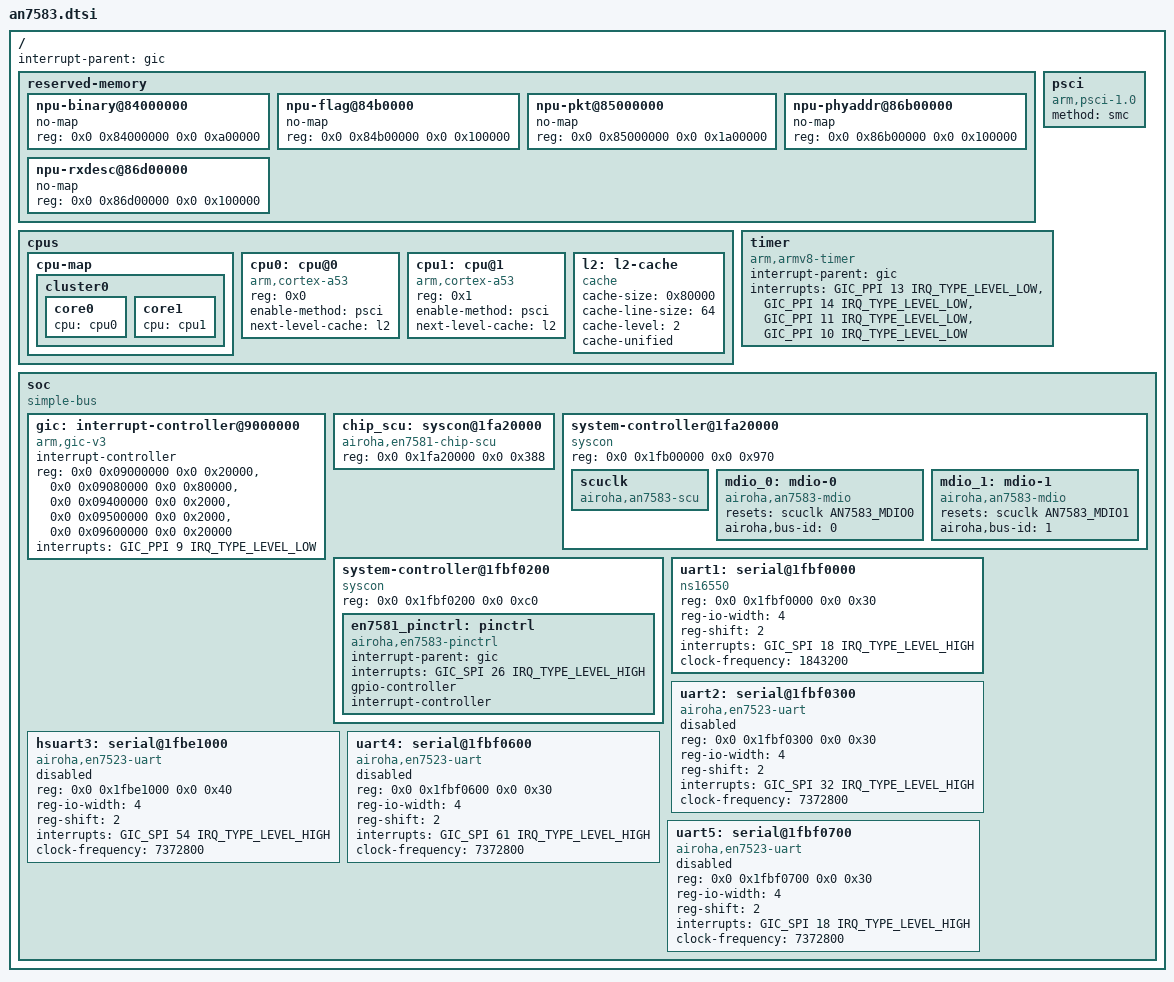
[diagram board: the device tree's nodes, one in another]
// SPDX-License-Identifier: (GPL-2.0-only OR BSD-2-Clause)

#include <dt-bindings/interrupt-controller/irq.h>
#include <dt-bindings/interrupt-controller/arm-gic.h>
#include <dt-bindings/clock/en7523-clk.h>
#include <dt-bindings/reset/airoha,an7583-reset.h>
#include <dt-bindings/leds/common.h>
#include <dt-bindings/thermal/thermal.h>

/ {
	interrupt-parent = <&gic>;
	#address-cells = <2>;
	#size-cells = <2>;

	reserved-memory {
		#address-cells = <2>;
		#size-cells = <2>;
		ranges;

		npu-binary@84000000 {
			no-map;
			reg = <0x0 0x84000000 0x0 0xa00000>;
		};

		npu-flag@84b0000 {
			no-map;
			reg = <0x0 0x84b00000 0x0 0x100000>;
		};

		npu-pkt@85000000 {
			no-map;
			reg = <0x0 0x85000000 0x0 0x1a00000>;
		};

		npu-phyaddr@86b00000 {
			no-map;
			reg = <0x0 0x86b00000 0x0 0x100000>;
		};

		npu-rxdesc@86d00000 {
			no-map;
			reg = <0x0 0x86d00000 0x0 0x100000>;
		};
	};

	psci {
		compatible = "arm,psci-1.0";
		method = "smc";
	};

	cpus {
		#address-cells = <1>;
		#size-cells = <0>;

		cpu-map {
			cluster0 {
				core0 {
					cpu = <&cpu0>;
				};

				core1 {
					cpu = <&cpu1>;
				};
			};
		};

		cpu0: cpu@0 {
			device_type = "cpu";
			compatible = "arm,cortex-a53";
			reg = <0x0>;
			enable-method = "psci";
			next-level-cache = <&l2>;
			#cooling-cells = <2>;
		};

		cpu1: cpu@1 {
			device_type = "cpu";
			compatible = "arm,cortex-a53";
			reg = <0x1>;
			enable-method = "psci";
			next-level-cache = <&l2>;
			#cooling-cells = <2>;
		};

		l2: l2-cache {
			compatible = "cache";
			cache-size = <0x80000>;
			cache-line-size = <64>;
			cache-level = <2>;
			cache-unified;
		};
	};

	timer {
		compatible = "arm,armv8-timer";
		interrupt-parent = <&gic>;
		interrupts = <GIC_PPI 13 IRQ_TYPE_LEVEL_LOW>,
			     <GIC_PPI 14 IRQ_TYPE_LEVEL_LOW>,
			     <GIC_PPI 11 IRQ_TYPE_LEVEL_LOW>,
			     <GIC_PPI 10 IRQ_TYPE_LEVEL_LOW>;
	};

	soc {
		compatible = "simple-bus";
		#address-cells = <2>;
		#size-cells = <2>;
		ranges;

		gic: interrupt-controller@9000000 {
			compatible = "arm,gic-v3";
			interrupt-controller;
			#interrupt-cells = <3>;
			#address-cells = <1>;
			#size-cells = <1>;
			reg = <0x0 0x09000000 0x0 0x20000>,
			      <0x0 0x09080000 0x0 0x80000>,
			      <0x0 0x09400000 0x0 0x2000>,
			      <0x0 0x09500000 0x0 0x2000>,
			      <0x0 0x09600000 0x0 0x20000>;
			interrupts = <GIC_PPI 9 IRQ_TYPE_LEVEL_LOW>;
		};

		chip_scu: syscon@1fa20000 {
			compatible = "airoha,en7581-chip-scu", "syscon";
			reg = <0x0 0x1fa20000 0x0 0x388>;
		};

		system-controller@1fa20000 {
			compatible = "syscon", "simple-mfd";
			reg = <0x0 0x1fb00000 0x0 0x970>;

			scuclk: scuclk {
				compatible = "airoha,an7583-scu";
				#clock-cells = <1>;
				#reset-cells = <1>;
			};

			mdio_0: mdio-0 {
				compatible = "airoha,an7583-mdio";
				resets = <&scuclk AN7583_MDIO0>;

				airoha,bus-id = <0>;
			};

			mdio_1: mdio-1 {
				compatible = "airoha,an7583-mdio";
				resets = <&scuclk AN7583_MDIO1>;

				airoha,bus-id = <1>;
			};
		};

		system-controller@1fbf0200 {
			compatible = "syscon", "simple-mfd";
			reg = <0x0 0x1fbf0200 0x0 0xc0>;

			en7581_pinctrl: pinctrl {
				compatible = "airoha,en7583-pinctrl";

				interrupt-parent = <&gic>;
				interrupts = <GIC_SPI 26 IRQ_TYPE_LEVEL_HIGH>;

				gpio-controller;
				#gpio-cells = <2>;

				interrupt-controller;
				#interrupt-cells = <2>;
			};
		};

		uart1: serial@1fbf0000 {
			compatible = "ns16550";
			reg = <0x0 0x1fbf0000 0x0 0x30>;
			reg-io-width = <4>;
			reg-shift = <2>;
			interrupts = <GIC_SPI 18 IRQ_TYPE_LEVEL_HIGH>;
			clock-frequency = <1843200>;
		};

		uart2: serial@1fbf0300 {
			compatible = "airoha,en7523-uart";
			reg = <0x0 0x1fbf0300 0x0 0x30>;
			reg-io-width = <4>;
			reg-shift = <2>;
			interrupts = <GIC_SPI 32 IRQ_TYPE_LEVEL_HIGH>;
			clock-frequency = <7372800>;

			status = "disabled";
		};

		hsuart3: serial@1fbe1000 {
			compatible = "airoha,en7523-uart";
			reg = <0x0 0x1fbe1000 0x0 0x40>;
			reg-io-width = <4>;
			reg-shift = <2>;
			interrupts = <GIC_SPI 54 IRQ_TYPE_LEVEL_HIGH>;
			clock-frequency = <7372800>;

			status = "disabled";
		};

		uart4: serial@1fbf0600 {
			compatible = "airoha,en7523-uart";
			reg = <0x0 0x1fbf0600 0x0 0x30>;
			reg-io-width = <4>;
			reg-shift = <2>;
			interrupts = <GIC_SPI 61 IRQ_TYPE_LEVEL_HIGH>;
			clock-frequency = <7372800>;

			status = "disabled";
		};

		uart5: serial@1fbf0700 {
			compatible = "airoha,en7523-uart";
			reg = <0x0 0x1fbf0700 0x0 0x30>;
			reg-io-width = <4>;
			reg-shift = <2>;
			interrupts = <GIC_SPI 18 IRQ_TYPE_LEVEL_HIGH>;
			clock-frequency = <7372800>;

			status = "disabled";
		};
	};
};
